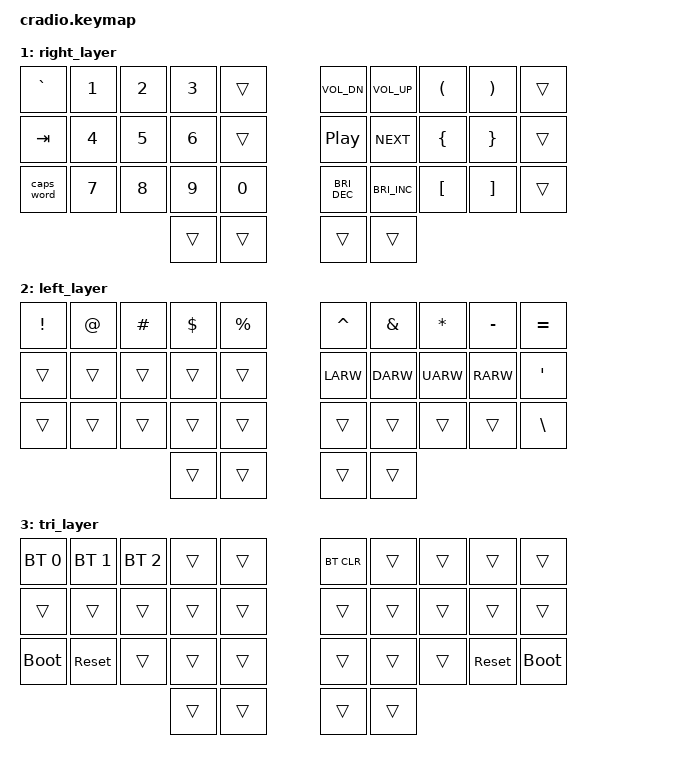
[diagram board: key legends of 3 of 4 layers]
// Copyright (c) 2022 The ZMK Contributors
// SPDX-License-Identifier: MIT

#include <behaviors.dtsi>
#include <dt-bindings/zmk/keys.h>
#include <dt-bindings/zmk/bt.h>

// Home row mods macro

#define HRML(k1,k2,k3,k4) &ht LSHFT k1  &ht LCTRL k2  &ht LGUI k3  &ht LALT k4
#define HRMR(k1,k2,k3,k4) &ht RALT  k1  &ht RGUI  k2  &ht RCTRL k3  &ht RSHFT k4

#define COMBO(NAME, BINDINGS, KEYPOS, LAYERS) \
  combo_##NAME { \
    bindings = <BINDINGS>; \
    timeout-ms = <100>; \
    key-positions = <KEYPOS>; \
    layers = <LAYERS>; \
  };

/ {
    behaviors {
        ht: hold_tap {
            compatible = "zmk,behavior-hold-tap";
            #binding-cells = <2>;
            flavor = "balanced";
            tapping-term-ms = <220>;
            quick-tap-ms = <150>;
            require-prior-idle-ms = <100>;
            bindings = <&kp>, <&kp>;
        };
    };

    combos {
        compatible = "zmk,combos";
    };

    conditional_layers {
        compatible = "zmk,conditional-layers";
        tri_layer {
            if-layers = <1 2>;
            then-layer = <3>;
        };
    };

    keymap {
        compatible = "zmk,keymap";
        default_layer {
            bindings = <
        //╭──────────┬──────────┬──────────┬──────────┬──────────╮   ╭──────────┬──────────┬──────────┬──────────┬──────────╮
        //│  Q       │  W       │  E       │  R       │  T       │   │  Y       │  U       │  I       │  O       │  P       │
            &kp Q      &kp W      &kp E      &kp R      &kp T          &kp Y      &kp U      &kp I      &kp O      &kp P
        //├──────────┼──────────┼──────────┼──────────┼──────────┤   ├──────────┼──────────┼──────────┼──────────┼──────────┤
        //│  A       │  S       │  D       │  F       │  G       │   │  H       │  J       │  K       │  L       │   ;      │
            HRML(A,        S,         D,         F)     &kp G          &kp H      HRMR(J,        K,         L,       SEMI)
        //├──────────┼──────────┼──────────┼──────────┼──────────┤   ├──────────┼──────────┼──────────┼──────────┼──────────┤
        //│  Z       │  X       │  C       │  V       │  B       │   │  N       │  M       │ , <      │ . >      │ / ?      │
            &kp Z      &kp X      &kp C      &kp V      &kp B          &kp N      &kp M      &kp COMMA  &kp DOT    &kp FSLH
        //╰──────────┴──────────┴──────────┼──────────┼──────────┤   ├──────────┼──────────┼──────────┴──────────┴──────────╯
                                            &lt 2 ESC   &kp SPACE     &kp ENTER  &lt 1 BSPC 
        //                                 ╰──────────┴──────────╯   ╰──────────┴──────────╯
            >;
        };

        right_layer {
            bindings = <
        //╭──────────┬──────────┬──────────┬──────────┬──────────╮   ╭──────────┬──────────┬──────────┬──────────┬──────────╮
        //│    `     │     1    │     2    │     3    │          │   │ VOL DOWN │  VOL UP  │    (     │    )     │          │
            &kp GRAVE   &kp N1     &kp N2     &kp N3     &trans     &kp C_VOL_DN &kp C_VOL_UP   &kp LPAR  &kp RPAR  &trans
        //├──────────┼──────────┼──────────┼──────────┼──────────┤   ├──────────┼──────────┼──────────┼──────────┼──────────┤
        //│    TAB   │    4     │    5     │     6    │          │   │Play/Pause│   Next   │    {     │    }     │          │
            &kp TAB     &kp N4     &kp N5     &kp N6     &trans     &kp C_PLAY_PAUSE &kp C_NEXT &kp LBRC   &kp RBRC   &trans
        //├──────────┼──────────┼──────────┼──────────┼──────────┤   ├──────────┼──────────┼──────────┼──────────┼──────────┤
        //│   CAPS   │    7     │    8     │     9    │    0     │   │Bright DWN│Bright UP │    [     │    ]     │          │
          &caps_word    &kp N7     &kp N8     &kp N9    &kp N0   &kp C_BRI_DEC &kp C_BRI_INC &kp LBKT   &kp RBKT   &trans
        //╰──────────┴──────────┴──────────┼──────────┼──────────┤   ├──────────┼──────────┼──────────┴──────────┴──────────╯
                                             &trans      &trans        &trans     &trans
        //                                 ╰──────────┴──────────╯   ╰──────────┴──────────╯
            >;
        };

        left_layer {
            bindings = <
        //╭──────────┬──────────┬──────────┬──────────┬──────────╮   ╭──────────┬──────────┬──────────┬──────────┬──────────╮
        //│    !     │  @       │   #      │   $      │    %     │   │  ^       │  &       │  *       │  -       │   =      │
            &kp EXCL    &kp AT    &kp HASH   &kp DLLR   &kp PRCNT      &kp CARET  &kp AMPS   &kp ASTRK  &kp MINUS  &kp EQUAL
        //├──────────┼──────────┼──────────┼──────────┼──────────┤   ├──────────┼──────────┼──────────┼──────────┼──────────┤
        //│          │          │          │          │          │   │   LEFT   │   DOWN   │    UP    │  RIGHT   │  ' "     │
            &trans      &trans     &trans     &trans    &trans         &kp LARW   &kp DARW   &kp UARW   &kp RARW   &kp SQT
        //├──────────┼──────────┼──────────┼──────────┼──────────┤   ├──────────┼──────────┼──────────┼──────────┼──────────┤
        //│          │          │          │          │          │   │          │          │          │          │    \     │
            &trans     &trans     &trans     &trans     &trans          &trans    &trans      &trans      &trans   &kp BSLH
        //╰──────────┴──────────┴──────────┼──────────┼──────────┤   ├──────────┼──────────┼──────────┴──────────┴──────────╯
                                             &trans     &trans         &trans     &trans
        //                                 ╰──────────┴──────────╯   ╰──────────┴──────────╯
            >;
        };

        tri_layer {
            bindings = <
        //╭──────────┬──────────┬──────────┬──────────┬──────────╮   ╭──────────┬──────────┬──────────┬──────────┬──────────╮
        //│ PROFILE 0│ PROFILE 1│ PROFILE 2│          │          │   │ CLEAR BT │          │          │          │          │
        &bt BT_SEL 0 &bt BT_SEL 1 &bt BT_SEL 2 &trans   &trans        &bt BT_CLR   &trans     &trans     &trans    &trans
        //├──────────┼──────────┼──────────┼──────────┼──────────┤   ├──────────┼──────────┼──────────┼──────────┼──────────┤
        //│          │          │          │          │          │   │          │          │          │          │          │
            &trans      &trans     &trans     &trans     &trans        &trans     &trans     &trans     &trans    &trans
        //├──────────┼──────────┼──────────┼──────────┼──────────┤   ├──────────┼──────────┼──────────┼──────────┼──────────┤
        //│BOOTLOADER│  RESET   │          │          │          │   │          │          │          │ RESET    │BOOTLOADER│ 
           &bootloader &sys_reset  &trans      &trans     &trans         &trans     &trans     &trans  &sys_reset &bootloader
        //╰──────────┴──────────┴──────────┼──────────┼──────────┤   ├──────────┼──────────┼──────────┴──────────┴──────────╯
                                             &trans     &trans         &trans     &trans
        //                                 ╰──────────┴──────────╯   ╰──────────┴──────────╯
            >;
        };
    };
};
